# MEC1322 register map
Vendor: Microchip Technology Inc.; Series: ARMCM4F; File version: 1.0
CPU: CM4 r1p0, little endian, MPU, FPU, 3 interrupt priority bits
Registers are 32-bit, read-write, reset 0x0 unless marked. A register's access mark holds for its fields unless they carry their own. Offsets are from the block's base; [hi:lo] are bit positions; lines under a group give offsets from that group; {n}, {i} and the like mark numbered series.

## PWM — This block generates a PWM output that can be used to control 4-wire fans, blinking LEDs, and other similar devices. Each PWM can generate an arbitrary duty cycle output at frequencies from less than 0.1 Hz to 24 MHz. The PWM controller can also used to generate the. PROCHOT output and Speaker output.
Base 0x40005800
{0x0+0x10*i} CH[{i}] (i=0..3) group — Channel implemented will have these registers to determine that channel's operation.
  0x00 COUNTER_ON_TIME — This field determine both the frequency and duty cycle of the PWM signal. When this field is set to zero and the PWMX_COUNTER_OFF_-TIME is not set to zero, the PWM_OUTPUT is held low (Full Off).
  0x04 COUNTER_OFF_TIME — This field determine both the frequency and duty cycle of the PWM signal. When this field is set to zero, the PWM_OUTPUT is held high (Full On).
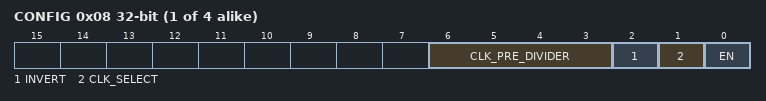
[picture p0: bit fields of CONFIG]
  0x08 CONFIG — PWMx CONFIGURATION REGISTER
    [6:3] CLK_PRE_DIVIDER — The Clock source is then divided by the value of Pre-Divider+1 and the resulting signal determines the rate at which the down counter will be decremented.
    [2] INVERT — INVERT 1= PWM_OUTPUT ON State is active low, 0=PWM_OUTPUT ON State is active high
    [1] CLK_SELECT — CLOCK_SELECT This bit determines the clock source used by the PWM duty cycle and frequency control logic. 1=CLOCK_LOW. 0=CLOCK_HIGH
    [0] EN — PWM_ENABLE 1=Enabled (default), 0=Disabled (gates clocks to save power)

## SPI — The General Purpose Serial Peripheral Interface (GP-SPI) may be used to communicate with various peripheral devices, e.g., EEPROMS, DACs, ADCs, that use a standard Serial Peripheral Interface.
Base 0x40009400
{0x0+0x80*i} CH[{i}] (i=0..1) group — Channel implemented will have these registers to determine that channel's operation.
  0x00 ENABLE reset 0xF (reset mask 0xFFFF) — [0:0] 1=Enabled. The device is fully operational. 0=Disabled. Clocks are gated to conserve power and the SPDOUT and SPI_CLK signals are set to their inactive state
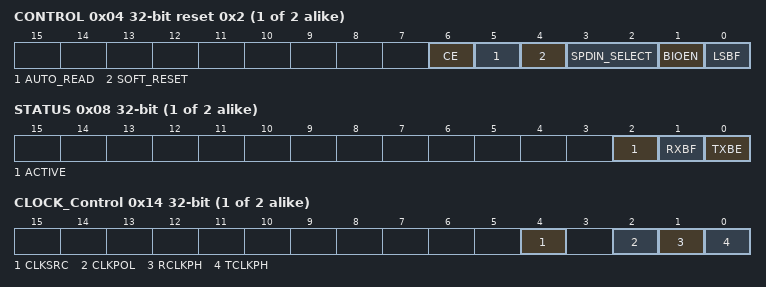
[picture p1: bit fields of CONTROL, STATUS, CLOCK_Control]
  0x04 CONTROL reset 0x2 — SPI Control
    [6] CE — SPI Chip Select Enable. 1= SPI_CS# output signal is asserted, i.e., driven to logic '0' 0= SPI_CS# output signal is deasserted, i.e., driven to logic '1'
    [5] AUTO_READ — Auto Read Enable. 1=A read of the SPI RX_DATA Register will clear both the RXBF status bit and the TXBE status bit. 0=A read of the SPI RX_DATA Register will clear the RXBF status bit. The TXBE status bit will not be modified
    [4] SOFT_RESET — Soft Reset is a self-clearing bit. Writing zero to this bit has no effect. Writing a one to this bit resets the entire SPI Interface, including all counters and registers back to their initial state.
    [3:2] SPDIN_SELECT — [3:2] 1xb=SPDIN1 and SPDIN2. Select this option for Dual Mode [3:2] 01b=SPDIN2 only. Select this option for Half Duplex [3:2] 00b=SPDIN1 only. Select this option for Full Duplex
    [1] BIOEN — Bidirectional Output Enable control. 1=The SPDOUT_Direction signal configures the SPDOUT signal as an output. 0=The SPDOUT_Direction signal configures the SPDOUT signal as an input.
    [0] LSBF — Least Significant Bit First. 1= The data is transferred in LSB-first order. 0= The data is transferred in MSB-first order. (default)
  0x08 STATUS ro — SPI Status
    [2] ACTIVE — ACTIVE status
    [1] RXBF — 1=RX_Data buffer is full, 0=RX_Data buffer is not full
    [0] TXBE — 1=TX_Data buffer is empty, 0=TX_Data buffer is not empty
  0x0C TX_DATA — [7:0] A write to this register when the Tx_Data buffer is empty (TXBE in the SPI Status Register is '1') initiates a SPI transaction.
  0x10 RX_DATA — [7:0] This register is used to read the value returned by the external SPI device.
  0x14 CLOCK_Control — SPI Clock Control. This register should not be changed during an active SPI transaction.
    [4] CLKSRC — 1=2MHz, 0=48 MHz Ring Oscillator
    [2] CLKPOL — 1=The SPI_CLK signal is high when the interface is idle and the first clock edge is a falling edge. 0=The SPI_CLK is low when the interface is idle and the first clock edge is a rising edge
    [1] RCLKPH — 1=Valid data on SPDIN signal is expected after the first SPI_CLK edge. This data is sampled on the second and following even SPI_CLK edges (i.e., sample data on falling edge). 0=Valid data is expected on the SPDIN signal on the first SPI_CLK edge. This data is sampled on the first and following odd SPI_-CLK edges (i.e., sample data on rising edge)
    [0] TCLKPH — 1=Valid data is clocked out on the first SPI_CLK edge on SPDOUT signal. The slave device should sample this data on the second and following even SPI_CLK edges (i.e., sample data on falling edge). 0=Valid data is clocked out on the SPDOUT signal prior to the first SPI_CLK edge. The slave device should sample this data on the first and following odd SPI_CLK edges (i.e., sample data on rising edge)
  0x18 CLOCK_GENERATOR reset 0x2 — [5:0] PRELOAD SPI Clock Generator Preload value.
